# CY8C4245AXI_483 register map
File version: 0.1
PSoC 4200
Registers are 32-bit, read-write, no defined reset value unless marked. A register's access mark holds for its fields unless they carry their own. Offsets are from the block's base; lines under a group give offsets from that group; [hi:lo] are bit positions; {n}, {i} and the like mark numbered series; 'fields as' and 'values as' point back to an identical list; <NAME> marks a mode.

## Memory map
0x00000000 Comp_1 — Comparator
0x00000000 IDAC_1 — IDAC
0x00000000 PWM

## Comp_1 — Comparator
Base 0x00000000
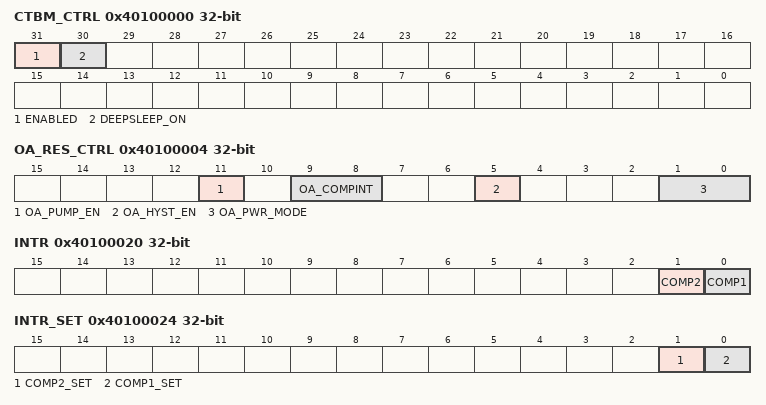
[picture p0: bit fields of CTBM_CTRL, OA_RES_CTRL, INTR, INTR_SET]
0x40100000 CTBM_CTRL — Global CTB IP and power control
  [31] ENABLED — Selects component behavior in DeepSleep power mode
    0=DISABLE (CTB IP disabled (put analog in power down, open all switches)); 1=ENABLE (CTB IP enabledCTB IP enabled)
  [30] DEEPSLEEP_ON — Selects component behavior in DeepSleep power mode
    0=DISABLE (CTB IP disabled off during DeepSleep power mode); 1=ENABLE (CTB IP remains enabled during DeepSleep power mode (if ENABLED=1))
0x40100004 OA_RES_CTRL — Comparator and resistor control
  [11] OA_PUMP_EN — Selects pump
    0=DISABLE (Pump disabled); 1=ENABLE (Pump enabled)
  [9:8] OA_COMPINT — Selects comparator edge detect
    0=DISABLE (Disabled); 1=RISING (Rising edge); 2=FALLING (Falling edge); 3=BOTH (Both rising and falling edges)
  [5] OA_HYST_EN — Selects hysteresis (10mV)
    0=DISABLE (Hysteresis disabled); 1=ENABLE (Hysteresis enabled)
  [1:0] OA_PWR_MODE — Selects speed for comparator
    0=OFF; 1=SLOW (Slow speed); 2=MED (Medium speed); 3=FAST (Fast speed)
0x4010000C COMP_STAT — Comparator status
  [16] OA_COMP ro — Current comparator status
0x40100020 INTR — Interrupt request register
  [1] COMP2 — Comparator #2 Interrupt: hardware sets this interrupt when comparator 0 triggers. Write with '1' to clear bit.
  [0] COMP1 — Comparator #1 Interrupt: hardware sets this interrupt when comparator 0 triggers. Write with '1' to clear bit.
0x40100024 INTR_SET — Interrupt request set register
  [1] COMP2_SET — Write with '1' to set corresponding bit in interrupt request register.
  [0] COMP1_SET — Write with '1' to set corresponding bit in interrupt request register.
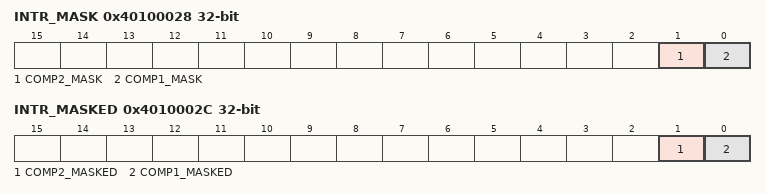
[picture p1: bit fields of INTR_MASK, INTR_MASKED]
0x40100028 INTR_MASK — Interrupt request mask
  [1] COMP2_MASK — Mask bit for corresponding bit in interrupt request register.
  [0] COMP1_MASK — Mask bit for corresponding bit in interrupt request register.
0x4010002C INTR_MASKED — Interrupt request masked
  [1] COMP2_MASKED ro — Logical and of corresponding request and mask bits.
  [0] COMP1_MASKED ro — Logical and of corresponding request and mask bits.
0x40100F00 OA_OFFSET_TRIM — Comparator offset trim
0x40100F04 OA_SLOPE_OFFSET_TRIM — Comparator slope offset drift trim
0x40100F08 OA_COMP_TRIM — Comparator trim

## IDAC_1 — IDAC
Base 0x00000000
0x40080004 CSD_IDAC_POLARITY
0x40080008 CSD_IDAC
0x4008FF00 CSD_TRIM1 — CSD IDAC TRIM1
0x4008FF04 CSD_TRIM2 — CSD IDAC TRIM2

## PWM
Base 0x00000000
0x40050108 COUNTER — Current counter value
0x4005010C CC — Compare / capture value
0x40050110 CC_BUF — Compare / capture buffer value
0x40050114 PERIOD — Period value
0x40050118 PERIOD_BUF — Period buffer value
